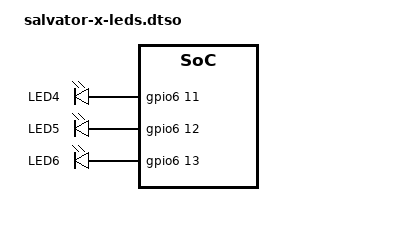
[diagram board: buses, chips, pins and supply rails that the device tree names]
// SPDX-License-Identifier: GPL-2.0
//
// Device Tree Overlay for GPIO LEDs on Salvator-X(S)
//
// Copyright (C) 2015 Glider bvba

/dts-v1/;
/plugin/;

#include <dt-bindings/gpio/gpio.h>

&{/} {
	leds {
		compatible = "gpio-leds";

		led4 {
			gpios = <&gpio6 11 GPIO_ACTIVE_HIGH>;
			label = "LED4";
		};
		led5 {
			gpios = <&gpio6 12 GPIO_ACTIVE_HIGH>;
			label = "LED5";
		};
		led6 {
			gpios = <&gpio6 13 GPIO_ACTIVE_HIGH>;
			label = "LED6";
		};
	};
};
